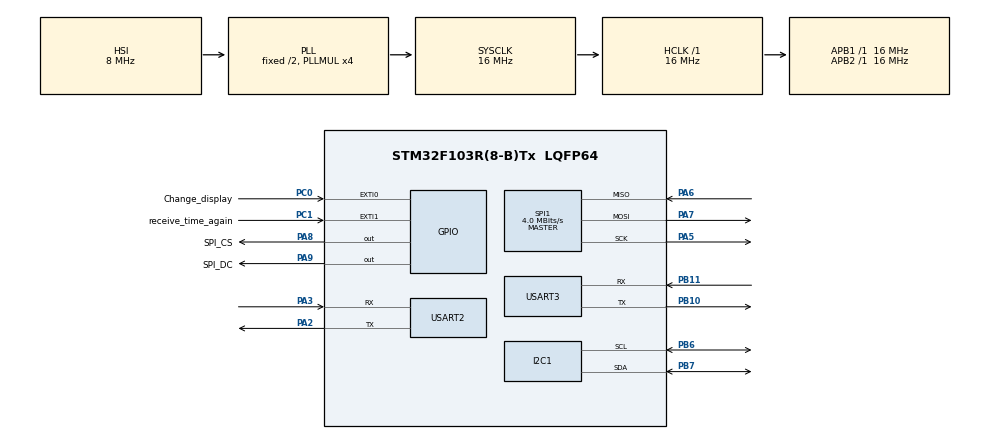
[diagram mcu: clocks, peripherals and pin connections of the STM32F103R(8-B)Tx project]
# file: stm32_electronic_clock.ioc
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Mcu.Family=STM32F1
NVIC.USART3_IRQn=true\:0\:0\:false\:false\:true\:true\:true
PA6.Mode=Full_Duplex_Master
PA7.Mode=Full_Duplex_Master
TIM3.Channel-Output\ Compare1\ No\ Output=TIM_CHANNEL_1
SPI1.VirtualType=VM_MASTER
PB10.Mode=Asynchronous
PA9.GPIO_Label=SPI_DC
PC0.GPIO_Label=Change_display
PC0.Signal=GPXTI0
PB11.Signal=USART3_RX
VP_SYS_VS_ND.Mode=No_Debug
RCC.SYSCLKSource=RCC_SYSCLKSOURCE_PLLCLK
ProjectManager.StackSize=0x400
PA3.Mode=Asynchronous
PA8.GPIO_Label=SPI_CS
PB11.Mode=Asynchronous
ProjectManager.TargetToolchain=STM32CubeIDE
SPI1.Direction=SPI_DIRECTION_2LINES
RCC.HCLKFreq_Value=16000000
RCC.APB2TimFreq_Value=16000000
TIM3.Period=250
PA9.Signal=GPIO_Output
PB6.Signal=I2C1_SCL
PA9.PinState=GPIO_PIN_RESET
PB6.Mode=I2C
SPI1.CalculateBaudRate=4.0 MBits/s
RCC.USBFreq_Value=16000000
RCC.AHBFreq_Value=16000000
PB10.Signal=USART3_TX
PA5.Signal=SPI1_SCK
board=custom
VP_TIM3_VS_no_output1.Mode=Output Compare1 No Output
PC1.GPIO_PuPd=GPIO_PULLUP
RCC.PLLMUL=RCC_PLL_MUL4
NVIC.TIM3_IRQn=true\:0\:0\:false\:false\:true\:true\:true
RCC.APB2Freq_Value=16000000
SPI1.Mode=SPI_MODE_MASTER
TIM3.Prescaler=64
PC1.GPIO_Label=receive_time_again
PB7.Signal=I2C1_SDA
PA8.Signal=GPIO_Output
Mcu.Name=STM32F103R(8-B)Tx
PA2.Signal=USART2_TX
PC0.GPIO_ModeDefaultEXTI=GPIO_MODE_IT_FALLING
RCC.SYSCLKFreq_VALUE=16000000
Mcu.Package=LQFP64
PA6.Signal=SPI1_MISO
USART2.VirtualMode=VM_ASYNC
USART3.VirtualMode=VM_ASYNC
PB7.Mode=I2C
ProjectManager.HeapSize=0x200
NVIC.PriorityGroup=NVIC_PRIORITYGROUP_4
PC1.GPIO_ModeDefaultEXTI=GPIO_MODE_IT_FALLING
RCC.APB1TimFreq_Value=16000000
PA2.Mode=Asynchronous
TIM3.TIM_MasterOutputTrigger=TIM_TRGO_ENABLE
PC0.GPIO_PuPd=GPIO_PULLUP
RCC.APB1Freq_Value=16000000
SPI1.BaudRatePrescaler=SPI_BAUDRATEPRESCALER_4
VP_TIM3_VS_ClockSourceINT.Mode=Internal
PC1.Signal=GPXTI1
PA3.Signal=USART2_RX
PA5.Mode=Full_Duplex_Master
PA7.Signal=SPI1_MOSI

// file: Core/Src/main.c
/* USER CODE BEGIN Header */
/**
  ******************************************************************************
  * @file           : main.c
  * @brief          : Main program body
  ******************************************************************************
  * @attention
  *
  * <h2><center>&copy; Copyright (c) 2021 STMicroelectronics.
  * All rights reserved.</center></h2>
  *
  * This software component is licensed by ST under BSD 3-Clause license,
  * the "License"; You may not use this file except in compliance with the
  * License. You may obtain a copy of the License at:
  *                        opensource.org/licenses/BSD-3-Clause
  *
  ******************************************************************************
  */
/* USER CODE END Header */
#include "main.h"

/* USER CODE BEGIN Includes */
#include "uart.h"
#include "stdio.h"
#include "ILI9341_LCD_input_data.h"
/* USER CODE END Includes */

I2C_HandleTypeDef hi2c1;

SPI_HandleTypeDef hspi1;

TIM_HandleTypeDef htim3;

UART_HandleTypeDef huart2;
UART_HandleTypeDef huart3;

void SystemClock_Config(void);
static void MX_GPIO_Init(void);
static void MX_I2C1_Init(void);
static void MX_SPI1_Init(void);
static void MX_TIM3_Init(void);
static void MX_USART2_UART_Init(void);
static void MX_USART3_UART_Init(void);

int main(void)
{

  /* MCU Configuration--------------------------------------------------------*/

  /* Reset of all peripherals, Initializes the Flash interface and the Systick. */
  HAL_Init();

  /* Configure the system clock */
  SystemClock_Config();

  /* Initialize all configured peripherals */
  MX_GPIO_Init();
  MX_I2C1_Init();
  MX_SPI1_Init();
  MX_TIM3_Init();
  MX_USART2_UART_Init();
  MX_USART3_UART_Init();
  /* USER CODE BEGIN 2 */
  printf("Start\n\r");
  setvbuf(stdin,NULL,_IONBF,0);
  ILI9341_LCD_input_data_init();
  /* USER CODE END 2 */

  /* Infinite loop */
  /* USER CODE BEGIN WHILE */
  while (1)
  {
	  ILI9341_LCD_input_data_update();
    /* USER CODE END WHILE */

  }
}

void SystemClock_Config(void)
{
  RCC_OscInitTypeDef RCC_OscInitStruct = {0};
  RCC_ClkInitTypeDef RCC_ClkInitStruct = {0};

  /** Initializes the RCC Oscillators according to the specified parameters
  * in the RCC_OscInitTypeDef structure.
  */
  RCC_OscInitStruct.OscillatorType = RCC_OSCILLATORTYPE_HSI;
  RCC_OscInitStruct.HSIState = RCC_HSI_ON;
  RCC_OscInitStruct.HSICalibrationValue = RCC_HSICALIBRATION_DEFAULT;
  RCC_OscInitStruct.PLL.PLLState = RCC_PLL_ON;
  RCC_OscInitStruct.PLL.PLLSource = RCC_PLLSOURCE_HSI_DIV2;
  RCC_OscInitStruct.PLL.PLLMUL = RCC_PLL_MUL4;
  if (HAL_RCC_OscConfig(&RCC_OscInitStruct) != HAL_OK)
  {
    Error_Handler();
  }
  /** Initializes the CPU, AHB and APB buses clocks
  */
  RCC_ClkInitStruct.ClockType = RCC_CLOCKTYPE_HCLK|RCC_CLOCKTYPE_SYSCLK
                              |RCC_CLOCKTYPE_PCLK1|RCC_CLOCKTYPE_PCLK2;
  RCC_ClkInitStruct.SYSCLKSource = RCC_SYSCLKSOURCE_PLLCLK;
  RCC_ClkInitStruct.AHBCLKDivider = RCC_SYSCLK_DIV1;
  RCC_ClkInitStruct.APB1CLKDivider = RCC_HCLK_DIV1;
  RCC_ClkInitStruct.APB2CLKDivider = RCC_HCLK_DIV1;

  if (HAL_RCC_ClockConfig(&RCC_ClkInitStruct, FLASH_LATENCY_0) != HAL_OK)
  {
    Error_Handler();
  }
}

static void MX_I2C1_Init(void)
{

  hi2c1.Instance = I2C1;
  hi2c1.Init.ClockSpeed = 100000;
  hi2c1.Init.DutyCycle = I2C_DUTYCYCLE_2;
  hi2c1.Init.OwnAddress1 = 0;
  hi2c1.Init.AddressingMode = I2C_ADDRESSINGMODE_7BIT;
  hi2c1.Init.DualAddressMode = I2C_DUALADDRESS_DISABLE;
  hi2c1.Init.OwnAddress2 = 0;
  hi2c1.Init.GeneralCallMode = I2C_GENERALCALL_DISABLE;
  hi2c1.Init.NoStretchMode = I2C_NOSTRETCH_DISABLE;
  if (HAL_I2C_Init(&hi2c1) != HAL_OK)
  {
    Error_Handler();
  }

}

static void MX_SPI1_Init(void)
{

  /* SPI1 parameter configuration*/
  hspi1.Instance = SPI1;
  hspi1.Init.Mode = SPI_MODE_MASTER;
  hspi1.Init.Direction = SPI_DIRECTION_2LINES;
  hspi1.Init.DataSize = SPI_DATASIZE_8BIT;
  hspi1.Init.CLKPolarity = SPI_POLARITY_LOW;
  hspi1.Init.CLKPhase = SPI_PHASE_1EDGE;
  hspi1.Init.NSS = SPI_NSS_SOFT;
  hspi1.Init.BaudRatePrescaler = SPI_BAUDRATEPRESCALER_4;
  hspi1.Init.FirstBit = SPI_FIRSTBIT_MSB;
  hspi1.Init.TIMode = SPI_TIMODE_DISABLE;
  hspi1.Init.CRCCalculation = SPI_CRCCALCULATION_DISABLE;
  hspi1.Init.CRCPolynomial = 10;
  if (HAL_SPI_Init(&hspi1) != HAL_OK)
  {
    Error_Handler();
  }

}

static void MX_TIM3_Init(void)
{

  TIM_ClockConfigTypeDef sClockSourceConfig = {0};
  TIM_MasterConfigTypeDef sMasterConfig = {0};
  TIM_OC_InitTypeDef sConfigOC = {0};

  htim3.Instance = TIM3;
  htim3.Init.Prescaler = 64;
  htim3.Init.CounterMode = TIM_COUNTERMODE_UP;
  htim3.Init.Period = 500;
  htim3.Init.ClockDivision = TIM_CLOCKDIVISION_DIV1;
  htim3.Init.AutoReloadPreload = TIM_AUTORELOAD_PRELOAD_DISABLE;
  if (HAL_TIM_Base_Init(&htim3) != HAL_OK)
  {
    Error_Handler();
  }
  sClockSourceConfig.ClockSource = TIM_CLOCKSOURCE_INTERNAL;
  if (HAL_TIM_ConfigClockSource(&htim3, &sClockSourceConfig) != HAL_OK)
  {
    Error_Handler();
  }
  if (HAL_TIM_OC_Init(&htim3) != HAL_OK)
  {
    Error_Handler();
  }
  sMasterConfig.MasterOutputTrigger = TIM_TRGO_ENABLE;
  sMasterConfig.MasterSlaveMode = TIM_MASTERSLAVEMODE_DISABLE;
  if (HAL_TIMEx_MasterConfigSynchronization(&htim3, &sMasterConfig) != HAL_OK)
  {
    Error_Handler();
  }
  sConfigOC.OCMode = TIM_OCMODE_TIMING;
  sConfigOC.Pulse = 0;
  sConfigOC.OCPolarity = TIM_OCPOLARITY_HIGH;
  sConfigOC.OCFastMode = TIM_OCFAST_DISABLE;
  if (HAL_TIM_OC_ConfigChannel(&htim3, &sConfigOC, TIM_CHANNEL_1) != HAL_OK)
  {
    Error_Handler();
  }

}

static void MX_USART2_UART_Init(void)
{

  huart2.Instance = USART2;
  huart2.Init.BaudRate = 115200;
  huart2.Init.WordLength = UART_WORDLENGTH_8B;
  huart2.Init.StopBits = UART_STOPBITS_1;
  huart2.Init.Parity = UART_PARITY_NONE;
  huart2.Init.Mode = UART_MODE_TX_RX;
  huart2.Init.HwFlowCtl = UART_HWCONTROL_NONE;
  huart2.Init.OverSampling = UART_OVERSAMPLING_16;
  if (HAL_UART_Init(&huart2) != HAL_OK)
  {
    Error_Handler();
  }

}

static void MX_USART3_UART_Init(void)
{

  huart3.Instance = USART3;
  huart3.Init.BaudRate = 115200;
  huart3.Init.WordLength = UART_WORDLENGTH_8B;
  huart3.Init.StopBits = UART_STOPBITS_1;
  huart3.Init.Parity = UART_PARITY_NONE;
  huart3.Init.Mode = UART_MODE_TX_RX;
  huart3.Init.HwFlowCtl = UART_HWCONTROL_NONE;
  huart3.Init.OverSampling = UART_OVERSAMPLING_16;
  if (HAL_UART_Init(&huart3) != HAL_OK)
  {
    Error_Handler();
  }
  /* USER CODE BEGIN USART3_Init 2 */
  __HAL_UART_ENABLE_IT(&huart3, UART_IT_RXNE);

  /* USER CODE END USART3_Init 2 */

}

static void MX_GPIO_Init(void)
{
  GPIO_InitTypeDef GPIO_InitStruct = {0};

  /* GPIO Ports Clock Enable */
  __HAL_RCC_GPIOC_CLK_ENABLE();
  __HAL_RCC_GPIOA_CLK_ENABLE();
  __HAL_RCC_GPIOB_CLK_ENABLE();

  /*Configure GPIO pin Output Level */
  HAL_GPIO_WritePin(GPIOA, SPI_CS_Pin|SPI_DC_Pin, GPIO_PIN_RESET);

  /*Configure GPIO pins : Change_display_Pin receive_time_again_Pin */
  GPIO_InitStruct.Pin = Change_display_Pin|receive_time_again_Pin;
  GPIO_InitStruct.Mode = GPIO_MODE_IT_FALLING;
  GPIO_InitStruct.Pull = GPIO_PULLUP;
  HAL_GPIO_Init(GPIOC, &GPIO_InitStruct);

  /*Configure GPIO pins : SPI_CS_Pin SPI_DC_Pin */
  GPIO_InitStruct.Pin = SPI_CS_Pin|SPI_DC_Pin;
  GPIO_InitStruct.Mode = GPIO_MODE_OUTPUT_PP;
  GPIO_InitStruct.Pull = GPIO_NOPULL;
  GPIO_InitStruct.Speed = GPIO_SPEED_FREQ_LOW;
  HAL_GPIO_Init(GPIOA, &GPIO_InitStruct);

  HAL_NVIC_EnableIRQ(EXTI0_IRQn);
  HAL_NVIC_EnableIRQ(EXTI1_IRQn);

}

void Error_Handler(void)
{
  __disable_irq();
  while (1)
  {
  }
}

/************************ (C) COPYRIGHT STMicroelectronics *****END OF FILE****/
